# f28003x_erad_global_regs register map
Vendor: Texas Instruments
Peripheral module from a debugger description file (folder C2000).
Address unit: 16 bits
Registers are 16-bit, read-write, no defined reset value unless marked. A register's access mark holds for its fields unless they carry their own. Offsets are as the file gives them; lines under a group give offsets from that group; [hi:lo] are bit positions; {n}, {i} and the like mark numbered series; 'fields as' and 'values as' point back to an identical list; <NAME> marks a mode.

## ERAD_GLOBAL_REGS — ERAD GLOBAL Registers
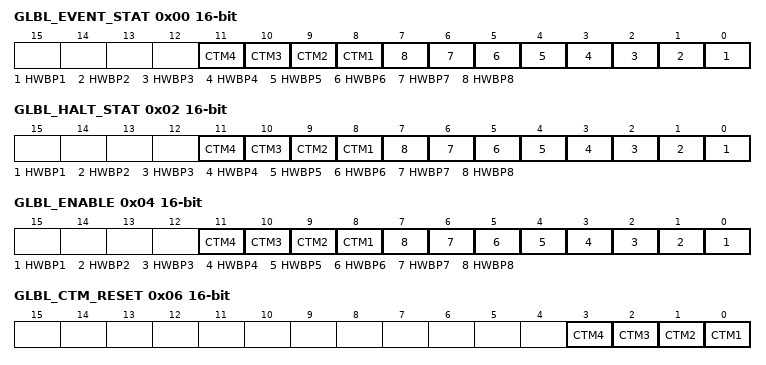
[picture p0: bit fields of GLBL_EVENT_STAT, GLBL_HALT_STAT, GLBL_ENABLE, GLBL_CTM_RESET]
0x00 GLBL_EVENT_STAT ro — Global Event Status Register
  [n+7] CTM{n} (n=1..4) — Counter Module Event Status
  [n-1] HWBP{n} (n=1..8) — Enhanced Bus Comparator (EBC) Module Event Status
0x02 GLBL_HALT_STAT ro — Global Halt Status Register
  [n+7] CTM{n} (n=1..4) — Counter Module Halt Status
  [n-1] HWBP{n} (n=1..8) — Enhanced Bus Comparator (EBC) Module Halt Status
0x04 GLBL_ENABLE — Global Enable Register
  [n+7] CTM{n} (n=1..4) — Counter Module Global Enable
  [n-1] HWBP{n} (n=1..8) — Enhanced Bus Comparator (EBC) Module Global Enable
0x06 GLBL_CTM_RESET — Global Counter Reset
  [n-1] CTM{n} (n=1..4) — Global Reset for the counters
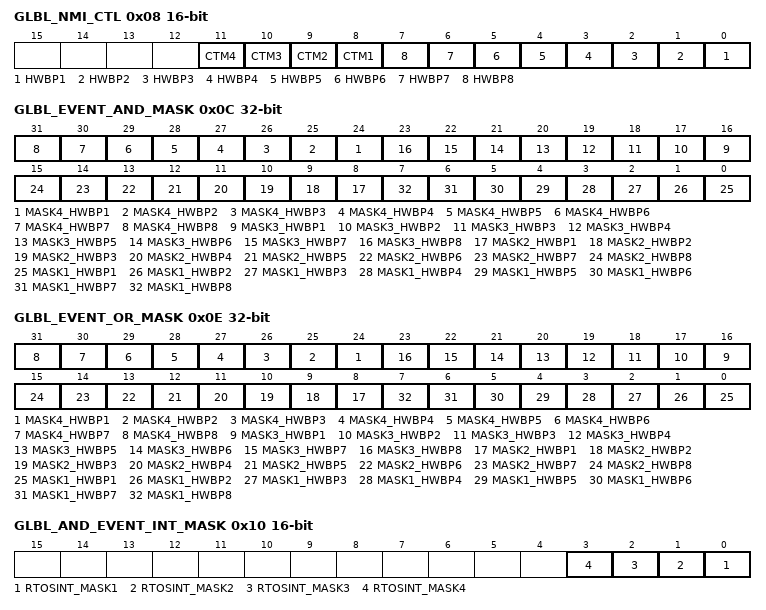
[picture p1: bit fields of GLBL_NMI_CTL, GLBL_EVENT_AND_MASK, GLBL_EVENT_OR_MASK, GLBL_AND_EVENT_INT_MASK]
0x08 GLBL_NMI_CTL — Global Debug NMI control
  [n+7] CTM{n} (n=1..4) — Counter non-maskable interrupt enable
  [n-1] HWBP{n} (n=1..8) — Enhanced Bus Comparator (EBC) non-maskable interrupt enable
0x0A GLBL_OWNER — Global Ownership
  [1:0] OWNER — Global Ownership Bits
0x0C GLBL_EVENT_AND_MASK 32-bit — Global Bus Comparator Event AND Mask Register
  [n+23] MASK4_HWBP{n} (n=1..8) — Enhanced Bus Comparator (EBC) AND Event Mask4
  [n+15] MASK3_HWBP{n} (n=1..8) — Enhanced Bus Comparator (EBC) AND Event Mask3
  [n+7] MASK2_HWBP{n} (n=1..8) — Enhanced Bus Comparator (EBC) AND Event Mask2
  [n-1] MASK1_HWBP{n} (n=1..8) — Enhanced Bus Comparator (EBC) AND Event Mask1
0x0E GLBL_EVENT_OR_MASK 32-bit — Global Bus Comparator Event OR Mask Register
  [n+23] MASK4_HWBP{n} (n=1..8) — Enhanced Bus Comparator (EBC) OR Event Mask4
  [n+15] MASK3_HWBP{n} (n=1..8) — Enhanced Bus Comparator (EBC) OR Event Mask3
  [n+7] MASK2_HWBP{n} (n=1..8) — Enhanced Bus Comparator (EBC) OR Event Mask2
  [n-1] MASK1_HWBP{n} (n=1..8) — Enhanced Bus Comparator (EBC) OR Event Mask1
0x10 GLBL_AND_EVENT_INT_MASK — Global AND Event Interrupt Mask Register
  [n-1] RTOSINT_MASK{n} (n=1..4) — RTOSINT generation mask for global AND events
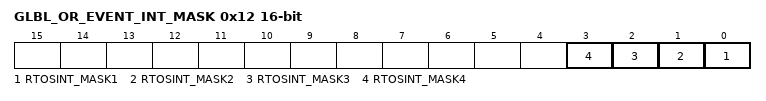
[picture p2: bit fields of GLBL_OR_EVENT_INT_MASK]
0x12 GLBL_OR_EVENT_INT_MASK — Global OR Event Interrupt Mask Register
  [n-1] RTOSINT_MASK{n} (n=1..4) — RTOSINT generation mask for global OR events
